# NANO100BN_v1 register map
File version: 1.0
Registers are 32-bit, read-write, reset 0x0 unless marked. A register's access mark holds for its fields unless they carry their own. Offsets are from the block's base; [hi:lo] are bit positions; {n}, {i} and the like mark numbered series.

## LCD — LCD Register Map
Base 0x400B0000
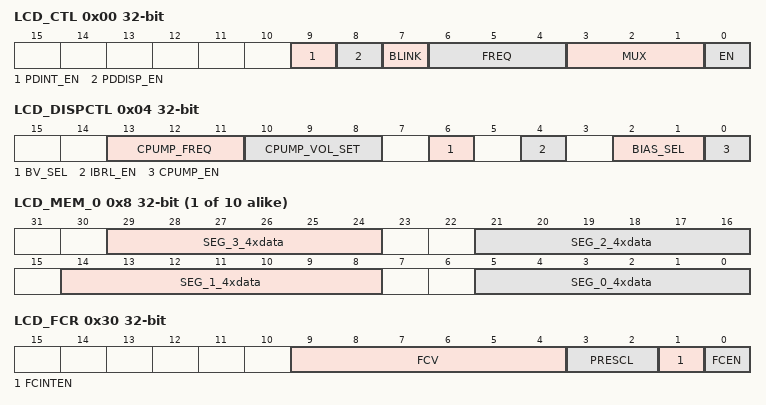
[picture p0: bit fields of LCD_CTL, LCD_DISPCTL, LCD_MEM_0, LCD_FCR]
0x00 LCD_CTL — LCD Control Register
  [9] PDINT_EN — Power Down Interrupt Enable. If the power down request is triggered from system management, LCD controller will execute the frame completely to avoid the DC component. When the frame is executed completely, the LCD power down interrupt signal is generated to inform system management that LCD controller is ready to enter power down state, if PDINT_EN is set to 1. Otherwise, if PDINT_EN is set to 0, the LCD power down interrupt signal is blocked and the interrupt is disabled to send to system management.
    0=Power Down Interrupt Disabled; 1=Power Down Interrupt Enabled
  [8] PDDISP_EN — Power Down Display Enable. The LCD can be programmed to be displayed or not be displayed at power down state by PDDISP_EN setting.
    0=LCD display Disabled ( LCD unlit) at power down state; 1=LCD display Enabled (LCD keeps the display) at power down state
  [7] BLINK — LCD Blinking Enable
    0=Blinking Disabled; 1=Blinking Enabled
  [6:4] FREQ — LCD Frequency Selection
    0=LCDCLK Divided by 32; 1=LCDCLK Divided by 64; 2=LCDCLK Divided by 96; 3=LCDCLK Divided by 128; 4=LCDCLK Divided by 192; 5=LCDCLK Divided by 256; 6=LCDCLK Divided by 384; 7=LCDCLK Divided by 512
  [3:1] MUX — Mux select
    0=Static; {v}=1/{v+1} duty (v=1..5)
  [0] EN — LCD Enable
    0=LCD controller operation Disabled; 1=LCD controller operation Enabled
0x04 LCD_DISPCTL — LCD Display Control Register
  [13:11] CPUMP_FREQ — Charge Pump Frequency Selection
    0=LCDCLK; 1=LCDCLK/2; 2=LCDCLK/4; 3=LCDCLK/8; 4=LCDCLK/16; 5=LCDCLK/32; 6=LCDCLK/64; 7=LCDCLK/128
  [10:8] CPUMP_VOL_SET — Charge Pump Voltage Selection
    0=2.7V; 1=2.8V; 2=2.9V; 3=3.0V; 4=3.1V; 5=3.2V; 6=3.3V; 7=3.4V
  [6] BV_SEL — Bias Voltage Type Selection. 0: Reserved. Note: The external resistor ladder should be connected to the V1 pin, V2 pin, V3 pin and VSS. The VLCD pin should also be connected to VDD.
    0=C-Type bias mode. Bias voltage source from internal bias generator; 1=R-Type bias mode. Bias voltage source from external bias generator
  [4] IBRL_EN — Internal Bias Reference ladder Enable
    0=Bias reference ladder Disabled; 1=Bias reference ladder Dnabled
  [2:1] BIAS_SEL — Bias Selection
    0=Static; 1=1/2 Bias; 2=1/3 Bias
  [0] CPUMP_EN — Charge Pump Enable
    0=Disabled; 1=Enabled
{0x8+4i} LCD_MEM_{i} (i=0..9) — LCD SEG3 ~ SEG0 data
  [29:24] SEG_3_4xdata, [21:16] SEG_2_4xdata, [14:8] SEG_1_4xdata, [5:0] SEG_0_4xdata
0x30 LCD_FCR — LCD frame counter control register
  [9:4] FCV — Frame Counter Top Value. These 6 bits contain the top value of the Frame counter.
  [3:2] PRESCL — Frame Counter Pre-scaler Value
    0=CLKframe/1; 1=CLKframe/2; 2=CLKframe/4; 3=CLKframe/8
  [1] FCINTEN — LCD Frame Counter Interrupt Enable
    0=Frame counter interrupt Disabled; 1=Frame counter interrupt Enabled
  [0] FCEN — LCD Frame Counter Enable
    0=Disabled; 1=Enabled
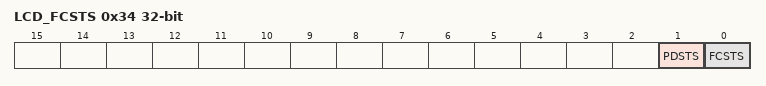
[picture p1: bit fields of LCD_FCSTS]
0x34 LCD_FCSTS — LCD frame counter status
  [1] PDSTS — Power-down Interrupt Status
    0=LCD power down is not ready; 1=LCD power down is ready
  [0] FCSTS — LCD Frame Counter Status
    0=Frame counter value does not reach FCV (Frame Count TOP value); 1=Frame counter value reaches FCV (Frame Count TOP value). If the FCINTEN is s enabled, the frame counter overflow Interrupt is generated

## WDT — WDT Register Map
Base 0x40004000
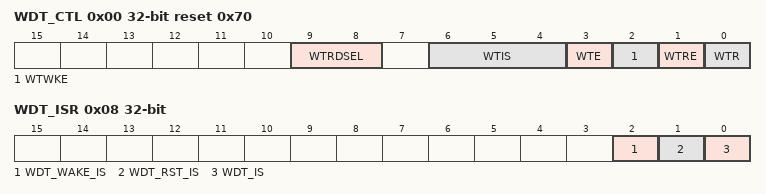
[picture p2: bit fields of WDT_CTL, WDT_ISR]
0x00 WDT_CTL reset 0x70 — Watchdog Timer Control Register
  [9:8] WTRDSEL — Watchdog Timer Reset Delay Select
  [6:4] WTIS — Watchdog Timer Interval Selection. This is a protected register. Please refer to open lock sequence to program it. These three bits select the time-out interval for the Watchdog timer. This count is free running counter. Please refer to
  [3] WTE — Watchdog Timer Enable. This is a protected register. Please refer to open lock sequence to program it.
    0=Watchdog timer Disabled (this action will reset the internal counter); 1=Watchdog timer Enabled
  [2] WTWKE — Watchdog Timer Wake-Up Function Enable. This is a protected register. Please refer to open lock sequence to program it.
    0=Watchdog timer Wake-up CPU function Disabled; 1=Wake-up function Enabled so that Watchdog timer time-out can wake up CPU from power-down mode
  [1] WTRE — Watchdog Timer Reset Function Enable. This is a protected register. Please refer to open lock sequence to program it. Setting this bit will enable the Watchdog timer reset function.
    0=Watchdog timer reset function Disabled; 1=Watchdog timer reset function Enabled
  [0] WTR — Clear Watchdog Timer. This is a protected register. Please refer to open lock sequence to program it. Set this bit will clear the Watchdog timer. Note: This bit will be auto cleared after few clock cycles.
    0=No effect; 1=Reset the contents of the Watchdog timer
0x04 WDT_IER — Watchdog Timer Interrupt Enable Register
  [0] WDT_IE — Watchdog Timer Interrupt Enable
    0=Watchdog timer interrupt Disabled; 1=Watchdog timer interrupt Enabled
0x08 WDT_ISR — Watchdog Timer Interrupt Status Register
  [2] WDT_WAKE_IS — Watchdog Timer Wake-up Status. If Watchdog timer causes system to wake up from power-down mode, this bit will be set to high. It must be cleared by software with a write "1" to this bit. Note1: When system in power-down mode and watchdog time-out, hardware will set WDT_WAKE_IS and WDT_IS. Note2: After one engine clock, this bit can be cleared by writing "1" to it
    0=Watchdog timer does not cause system wake-up; 1=Wake system up from power-down mode by Watchdog time-out
  [1] WDT_RST_IS — Watchdog Timer Reset Status. When the Watchdog timer initiates a reset, the hardware will set this bit. This flag can be read by software to determine the source of reset. Software is responsible to clear it manually by writing "1" to it. If WTRE is disabled, then the Watchdog timer has no effect on this bit. Note: This bit is read only, but can be cleared by writing "1" to it.
    0=Watchdog timer reset did not occur; 1=Watchdog timer reset occurs
  [0] WDT_IS — Watchdog Timer Interrupt Status. If the Watchdog timer interrupt is enabled, then the hardware will set this bit to indicate that the Watchdog timer interrupt has occurred. If the Watchdog timer interrupt is not enabled, then this bit indicates that a time-out period has elapsed. Note: This bit is read only, but can be cleared by writing "1" to it.
    0=Watchdog timer interrupt did not occur; 1=Watchdog timer interrupt occurs

## WWDT — WWDT Register Map
Base 0x40004100
0x00 WWDTRLD wo — Window Watchdog Timer Reload Counter Register
  [31:0] WWDTRLD — Window Watchdog Timer Reload Counter Register. Writing 0x00005AA5 to this register will reload the Window Watchdog Timer counter value to 0x3F. Note: SW only can write WWDTRLD when WWDT counter value between 0 and WINCMP. If SW writes WWDTRLD when WWDT counter value larger than WINCMP, WWDT will generate RESET signal.
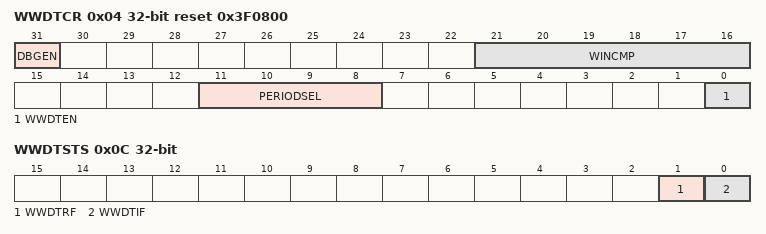
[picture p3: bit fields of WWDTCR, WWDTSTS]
0x04 WWDTCR reset 0x3F0800 — Window Watchdog Timer Control Register
  [31] DBGEN — WWDT Debug Enable
    0=WWDT stopped count if system is in Debug mode; 1=WWDT still counted even system is in Debug mode
  [21:16] WINCMP — WWDT Window Compare Register. Set this register to adjust the valid reload window. Note: SW only can write WWDTRLD when WWDT counter value between 0 and WINCMP. If SW writes WWDTRLD when WWDT counter value larger than WWCMP, WWDT will generate RESET signal.
  [11:8] PERIODSEL — WWDT Pre-scale Period Select. These three bits select the pre-scale for the WWDT counter period. Please refer to Table 5 17
  [0] WWDTEN — Window Watchdog Enable. Set this bit to enable Window Watchdog timer.
    0=Window Watchdog timer function Disabled; 1=Window Watchdog timer function Enabled
0x08 WWDT_IER — Window Watchdog Timer Interrupt Enable Register
  [0] WWDTIE — WWDT Interrupt Enable. Setting this bit will enable the Watchdog timer interrupt function.
    0=Watchdog timer interrupt function Disabled; 1=Watchdog timer interrupt function Enabled
0x0C WWDTSTS — Window Watchdog Timer Status Register
  [1] WWDTRF — WWDT Reset Flag. When WWDT counter down count to 0 or write WWDTRLD during WWDT counter larger than WINCMP, chip will be reset and this bit is set to 1. Software can write 1 to clear this bit to 0.
  [0] WWDTIF — WWDT Compare Match Interrupt Flag. When WWCMP match the WWDT counter, then this bit is set to 1. This bit will be cleared by software write 1 to this bit.
0x10 WWDTVAL ro reset 0x3F — Window Watchdog Timer Counter Value Register
  [5:0] WWDTVAL — WWDT Counter Value. This register reflects the counter value of window watchdog. This register is read only
